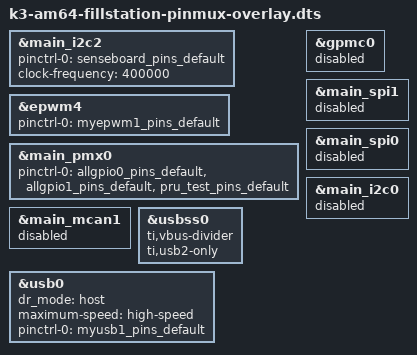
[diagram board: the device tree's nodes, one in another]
/dts-v1/;
/plugin/;

#include "k3.h"
#include "sysconfig-pinmux.dtsi"

/* Attach pinctrl to actual consumers */

&main_i2c2 {
    status = "okay";
    pinctrl-names = "default";
    pinctrl-0 = <&senseboard_pins_default>; 
    clock-frequency = <400000>;
};

&epwm4 {
    status = "okay";
    pinctrl-names = "default";
    pinctrl-0 = <&myepwm1_pins_default>; 
};

&main_pmx0 {
    pinctrl-names = "default";
    pinctrl-0 = <&allgpio0_pins_default &allgpio1_pins_default &pru_test_pins_default>;
};

/* Disable peripherals that conflict with our GPIO usages */
&gpmc0 {
    status = "disabled";
};

&main_spi1 {
    status = "disabled";
};

&main_spi0 {
    status = "disabled";
};

&main_mcan1 {
    status = "disabled";
};

/* I2C0_SCL (pad 0x260) is muxed as GPIO1_64 (QD stepper ENA), so main_i2c0
 * can't get its pins. It only hosts the board-ID EEPROM, which U-Boot reads
 * before Linux. /dev/i2c-2 is unaffected: aliases only pin i2c0/i2c1. */
&main_i2c0 {
    status = "disabled";
};

/* Enable USB0 in host mode for Pico 2 umbilical (CDC-ACM).
 * The SerDes phys/phy-names inherited from the base k3-am642-sk DTB are
 * removed with fdtput in build-fit-image.nix — overlays can't delete
 * properties from the base tree. We only need USB 2.0. */
&usbss0 {
    ti,vbus-divider;
    ti,usb2-only;
};

&usb0 {
    status = "okay";
    dr_mode = "host";
    maximum-speed = "high-speed";
    pinctrl-names = "default";
    pinctrl-0 = <&myusb1_pins_default>;
};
